VERSION "43"

NS_ :

BS_:

BU_: Lorem Ipsum Dolor

BO_ 256 Foo: 4 Lorem
 SG_ Voltage : 16|16@1+ (0.000976562,0) [0E-009|63.9990234375] "V" Vector__XXX
 SG_ Current : 0|16@1- (0.0625,0) [-2048|2047.9375] "A" Vector__XXX

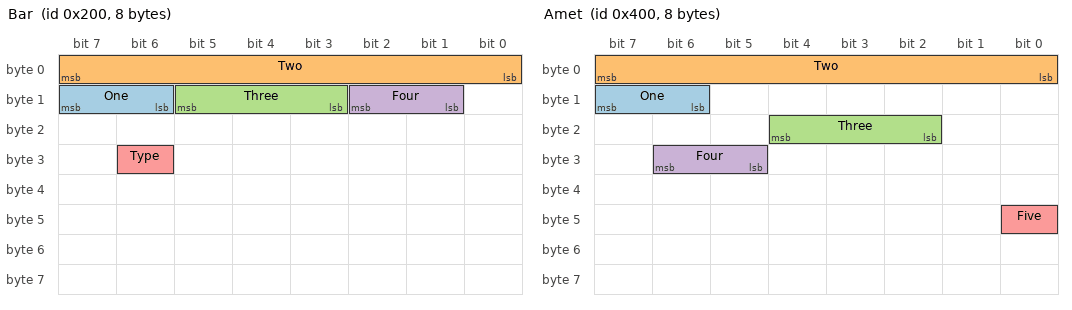
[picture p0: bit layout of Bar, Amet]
BO_ 512 Bar: 8 Ipsum
 SG_ One : 15|2@0+ (1,0) [0|3] "" Dolor
 SG_ Two : 7|8@0+ (0.39,0) [0.00|100] "%" Dolor
 SG_ Three : 13|3@0+ (1,0) [0|7] "" Dolor
 SG_ Four : 10|2@0+ (1,0) [0|3] "" Dolor
 SG_ Type : 30|1@0+ (1,0) [0|1] "boolean" Dolor

BO_ 768 _4WD: 8 Ipsum
 SG_ _4DRIVE : 13|3@0+ (1,0) [0|7] "" Dolor

BO_ 1024 Amet: 8 Sit
 SG_ One : 15|2@0+ (1,0) [0|3] "" Dolor
 SG_ Two : 7|8@0+ (0.39,0) [0.00|100] "%" Dolor
 SG_ Three : 20|3@0+ (1,0) [0|7] "" Dolor
 SG_ Four : 30|2@0+ (1,0) [0|3] "" Dolor
 SG_ Five : 40|1@0+ (1,0) [0|1] "boolean" Dolor

BO_ 1028 Dolor: 8 Sit
 SG_ OneFloat : 0|12@0+ (0.5,0) [0.00|130.00] "" Vector__XXX

BO_ 200 MultiplexTest: 8 SENSOR
 SG_ Multiplexor M : 0|4@1+ (1,0) [0|2] "" Vector__XXX
 SG_ UnmultiplexedSignal : 4|8@1+ (1,0) [0|4] "" Vector__XXX
 SG_ MultiplexedSignalZeroA m0 : 12|8@1+ (0.1,0) [0|3] "" Vector__XXX
 SG_ MultiplexedSignalZeroB m0 : 20|8@1+ (0.1,0) [0|3] "" Vector__XXX
 SG_ MultiplexedSignalOneA m1 : 12|8@1+ (0.1,0) [0|6] "" Vector__XXX
 SG_ MultiplexedSignalOneB m1 : 20|8@1+ (0.1,0) [0|6] "" Vector__XXX

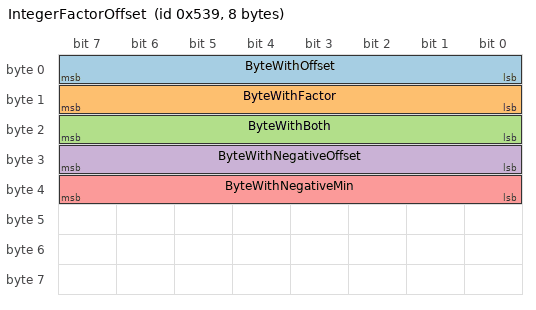
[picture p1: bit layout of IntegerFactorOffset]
BO_ 1337 IntegerFactorOffset: 8 Sit
 SG_ ByteWithOffset : 0|8@1+ (1,1) [1|256] "" Vector__XXX
 SG_ ByteWithFactor : 8|8@1+ (4,0) [0|1020] "" Vector__XXX
 SG_ ByteWithBoth : 16|8@1+ (2,16) [16|526] "" Vector__XXX
 SG_ ByteWithNegativeOffset : 24|8@1+ (1,-1) [0|255] "" Vector__XXX
 SG_ ByteWithNegativeMin : 32|8@1+ (1,-1) [-127|127] "" Vector__XXX

BO_ 600 Float32Test: 8 Ipsum
 SG_ Float32BigEndian : 7|32@0- (1,0) [-100|100] "" DBG
 SG_ Float32LittleEndian : 32|32@1- (1,0) [-100|100] "" DBG

BO_ 1344 NegativeFactorTest: 4 Sit
 SG_ UnsignedNegativeFactorSignal : 0|16@1+ (-1,0) [-65535|0] "" Vector__XXX
 SG_ WidthMoreThanMinMax : 16|10@1- (1,0) [-2|2] "" Vector__XXX

BO_ 1338 LargerIntsWithOffsets: 8 Sit
 SG_ Twelve : 0|12@1+ (1,-1000) [-1000|3000] "" XXX
 SG_ Sixteen : 12|16@1+ (1,-1000) [-1000|64535] "" XXX

BO_ 513 MsgWithoutSignals: 8 Ipsum

BO_ 9001 TruncatedBeSignal: 8 Ipsum
  SG_ Foo : 0|12@0- (1,0) [-100|100] "" Vector__XXX

BO_ 9002 TruncatedLeSignal: 8 Ipsum
  SG_ Foo : 0|12@1- (1,0) [-100|100] "" Vector__XXX

BO_ 2147488308 MsgExtendedId: 8 Sit
 SG_ Dummy : 15|2@0+ (1,0) [0|3] "" XXX

VAL_ 512 Three 0 "OFF" 1 "ON" 2 "ONER" 3 "ONEST";
VAL_ 512 Four 0 "Off" 1 "On" 2 "Oner" 3 "Onest";
VAL_ 512 Type 0 "0Off" 1 "1On";
VAL_ 768 _4DRIVE 0 "OFF" 1 "2WD" 2 "4WD" 3 "ALL";
VAL_ 1028 OneFloat 3 "Dolor" 5 "Other";

SIG_VALTYPE_ 600 Float32BigEndian : 1;
SIG_VALTYPE_ 600 Float32LittleEndian : 1;
